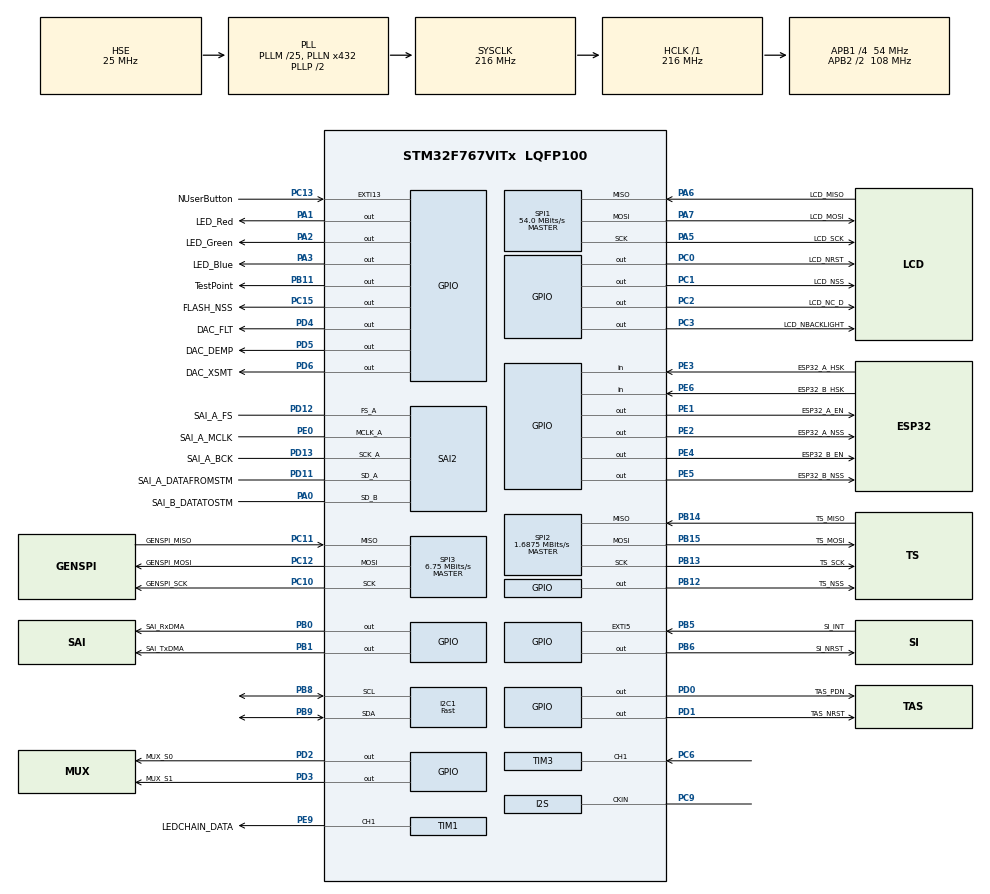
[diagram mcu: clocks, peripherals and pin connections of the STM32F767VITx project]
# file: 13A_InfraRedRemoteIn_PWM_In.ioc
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CORTEX_M7.CPU_DCache=Enabled
CORTEX_M7.CPU_ICache=Enabled
Dma.I2C1_RX.1.Direction=DMA_PERIPH_TO_MEMORY
Dma.I2C1_RX.1.FIFOMode=DMA_FIFOMODE_DISABLE
Dma.I2C1_RX.1.Instance=DMA1_Stream0
Dma.I2C1_RX.1.MemDataAlignment=DMA_MDATAALIGN_BYTE
Dma.I2C1_RX.1.MemInc=DMA_MINC_ENABLE
Dma.I2C1_RX.1.Mode=DMA_NORMAL
Dma.I2C1_RX.1.PeriphDataAlignment=DMA_PDATAALIGN_BYTE
Dma.I2C1_RX.1.PeriphInc=DMA_PINC_DISABLE
Dma.I2C1_RX.1.Priority=DMA_PRIORITY_HIGH
Dma.I2C1_TX.0.Direction=DMA_MEMORY_TO_PERIPH
Dma.I2C1_TX.0.FIFOMode=DMA_FIFOMODE_DISABLE
Dma.I2C1_TX.0.Instance=DMA1_Stream7
Dma.I2C1_TX.0.MemDataAlignment=DMA_MDATAALIGN_BYTE
Dma.I2C1_TX.0.MemInc=DMA_MINC_ENABLE
Dma.I2C1_TX.0.Mode=DMA_NORMAL
Dma.I2C1_TX.0.PeriphDataAlignment=DMA_PDATAALIGN_BYTE
Dma.I2C1_TX.0.PeriphInc=DMA_PINC_DISABLE
Dma.I2C1_TX.0.Priority=DMA_PRIORITY_HIGH
Dma.Request0=I2C1_TX
Dma.Request1=I2C1_RX
Dma.Request2=SPI1_TX
Dma.Request3=SAI2_A
Dma.Request4=SAI2_B
Dma.Request5=TIM1_CH1
Dma.Request6=SPI3_TX
Dma.SAI2_A.3.Direction=DMA_MEMORY_TO_PERIPH
Dma.SAI2_A.3.FIFOMode=DMA_FIFOMODE_DISABLE
Dma.SAI2_A.3.Instance=DMA2_Stream2
Dma.SAI2_A.3.MemDataAlignment=DMA_MDATAALIGN_WORD
Dma.SAI2_A.3.MemInc=DMA_MINC_ENABLE
Dma.SAI2_A.3.Mode=DMA_CIRCULAR
Dma.SAI2_A.3.PeriphDataAlignment=DMA_PDATAALIGN_WORD
Dma.SAI2_A.3.PeriphInc=DMA_PINC_DISABLE
Dma.SAI2_A.3.Priority=DMA_PRIORITY_HIGH
Dma.SAI2_B.4.Direction=DMA_PERIPH_TO_MEMORY
Dma.SAI2_B.4.FIFOMode=DMA_FIFOMODE_DISABLE
Dma.SAI2_B.4.Instance=DMA2_Stream6
Dma.SAI2_B.4.MemDataAlignment=DMA_MDATAALIGN_WORD
Dma.SAI2_B.4.MemInc=DMA_MINC_ENABLE
Dma.SAI2_B.4.Mode=DMA_CIRCULAR
Dma.SAI2_B.4.PeriphDataAlignment=DMA_PDATAALIGN_WORD
Dma.SAI2_B.4.PeriphInc=DMA_PINC_DISABLE
Dma.SAI2_B.4.Priority=DMA_PRIORITY_HIGH
Dma.SPI1_TX.2.Direction=DMA_MEMORY_TO_PERIPH
Dma.SPI1_TX.2.FIFOMode=DMA_FIFOMODE_ENABLE
Dma.SPI1_TX.2.FIFOThreshold=DMA_FIFO_THRESHOLD_FULL
Dma.SPI1_TX.2.Instance=DMA2_Stream3
Dma.SPI1_TX.2.MemBurst=DMA_MBURST_SINGLE
Dma.SPI1_TX.2.MemDataAlignment=DMA_MDATAALIGN_BYTE
Dma.SPI1_TX.2.MemInc=DMA_MINC_ENABLE
Dma.SPI1_TX.2.Mode=DMA_NORMAL
Dma.SPI1_TX.2.PeriphBurst=DMA_PBURST_SINGLE
Dma.SPI1_TX.2.PeriphDataAlignment=DMA_PDATAALIGN_BYTE
Dma.SPI1_TX.2.PeriphInc=DMA_PINC_DISABLE
Dma.SPI1_TX.2.Priority=DMA_PRIORITY_MEDIUM
Dma.SPI3_TX.6.Direction=DMA_MEMORY_TO_PERIPH
Dma.SPI3_TX.6.FIFOMode=DMA_FIFOMODE_ENABLE
Dma.SPI3_TX.6.FIFOThreshold=DMA_FIFO_THRESHOLD_FULL
Dma.SPI3_TX.6.Instance=DMA1_Stream5
Dma.SPI3_TX.6.MemBurst=DMA_MBURST_SINGLE
Dma.SPI3_TX.6.MemDataAlignment=DMA_MDATAALIGN_BYTE
Dma.SPI3_TX.6.MemInc=DMA_MINC_ENABLE
Dma.SPI3_TX.6.Mode=DMA_NORMAL
Dma.SPI3_TX.6.PeriphBurst=DMA_PBURST_SINGLE
Dma.SPI3_TX.6.PeriphDataAlignment=DMA_PDATAALIGN_BYTE
Dma.SPI3_TX.6.PeriphInc=DMA_PINC_DISABLE
Dma.SPI3_TX.6.Priority=DMA_PRIORITY_HIGH
Dma.TIM1_CH1.5.Direction=DMA_MEMORY_TO_PERIPH
Dma.TIM1_CH1.5.FIFOMode=DMA_FIFOMODE_ENABLE
Dma.TIM1_CH1.5.FIFOThreshold=DMA_FIFO_THRESHOLD_FULL
Dma.TIM1_CH1.5.Instance=DMA2_Stream1
Dma.TIM1_CH1.5.MemBurst=DMA_MBURST_SINGLE
Dma.TIM1_CH1.5.MemDataAlignment=DMA_MDATAALIGN_HALFWORD
Dma.TIM1_CH1.5.MemInc=DMA_MINC_ENABLE
Dma.TIM1_CH1.5.Mode=DMA_NORMAL
Dma.TIM1_CH1.5.PeriphBurst=DMA_PBURST_SINGLE
Dma.TIM1_CH1.5.PeriphDataAlignment=DMA_PDATAALIGN_HALFWORD
Dma.TIM1_CH1.5.PeriphInc=DMA_PINC_DISABLE
Dma.TIM1_CH1.5.Priority=DMA_PRIORITY_MEDIUM
I2C1.I2C_Speed_Mode=I2C_Fast
I2C1.Timing=0x6000030D
Mcu.Family=STM32F7
Mcu.Name=STM32F767VITx
Mcu.Package=LQFP100
NVIC.DMA1_Stream0_IRQn=true\:0\:0\:false\:false\:true\:false\:true
NVIC.DMA1_Stream5_IRQn=true\:0\:0\:false\:false\:true\:false\:true
NVIC.DMA1_Stream7_IRQn=true\:0\:0\:false\:false\:true\:false\:true
NVIC.DMA2_Stream1_IRQn=true\:0\:0\:false\:false\:true\:false\:true
NVIC.DMA2_Stream2_IRQn=true\:0\:0\:false\:false\:true\:false\:true
NVIC.DMA2_Stream3_IRQn=true\:0\:0\:false\:false\:true\:false\:true
NVIC.DMA2_Stream6_IRQn=true\:0\:0\:false\:false\:true\:false\:true
NVIC.EXTI15_10_IRQn=true\:0\:0\:false\:false\:true\:true\:true
NVIC.EXTI9_5_IRQn=true\:0\:0\:false\:false\:true\:true\:true
NVIC.I2C1_ER_IRQn=true\:0\:0\:false\:false\:true\:true\:true
NVIC.I2C1_EV_IRQn=true\:0\:0\:false\:false\:true\:true\:true
NVIC.PriorityGroup=NVIC_PRIORITYGROUP_4
NVIC.TIM1_TRG_COM_TIM11_IRQn=true\:0\:0\:false\:false\:true\:true\:true
NVIC.TIM3_IRQn=true\:0\:0\:false\:false\:true\:true\:true
PA0/WKUP.GPIO_Label=SAI_B_DATATOSTM
PA0/WKUP.Mode=SAI_B_SyncSlave
PA0/WKUP.Signal=SAI2_SD_B
PA1.GPIO_Label=LED_Red
PA1.Signal=GPIO_Output
PA13.GPIO_Label=SWDIO
PA13.Mode=Serial_Wire
PA13.Signal=SYS_JTMS-SWDIO
PA14.GPIO_Label=SWCLK
PA14.Mode=Serial_Wire
PA14.Signal=SYS_JTCK-SWCLK
PA2.GPIO_Label=LED_Green
PA2.Signal=GPIO_Output
PA3.GPIO_Label=LED_Blue
PA3.Signal=GPIO_Output
PA5.GPIO_Label=LCD_SCK
PA5.Mode=Full_Duplex_Master
PA5.Signal=SPI1_SCK
PA6.GPIO_Label=LCD_MISO
PA6.Mode=Full_Duplex_Master
PA6.Signal=SPI1_MISO
PA7.GPIO_Label=LCD_MOSI
PA7.Mode=Full_Duplex_Master
PA7.Signal=SPI1_MOSI
PB0.GPIO_Label=SAI_RxDMA
PB0.GPIO_Speed=GPIO_SPEED_FREQ_HIGH
PB0.Signal=GPIO_Output
PB1.GPIO_Label=SAI_TxDMA
PB1.GPIO_Speed=GPIO_SPEED_FREQ_HIGH
PB1.Signal=GPIO_Output
PB11.GPIO_Label=TestPoint
PB11.GPIO_Speed=GPIO_SPEED_FREQ_HIGH
PB11.PinState=GPIO_PIN_RESET
PB11.Signal=GPIO_Output
PB12.GPIO_Label=TS_NSS
PB12.Signal=GPIO_Output
PB13.GPIO_Label=TS_SCK
PB13.Mode=Full_Duplex_Master
PB13.Signal=SPI2_SCK
PB14.GPIO_Label=TS_MISO
PB14.Mode=Full_Duplex_Master
PB14.Signal=SPI2_MISO
PB15.GPIO_Label=TS_MOSI
PB15.Mode=Full_Duplex_Master
PB15.Signal=SPI2_MOSI
PB5.GPIO_Label=SI_INT
PB5.GPIO_ModeDefaultEXTI=GPIO_MODE_IT_FALLING
PB5.Signal=GPXTI5
PB6.GPIO_Label=SI_NRST
PB6.Signal=GPIO_Output
PB8.Mode=I2C
PB8.Signal=I2C1_SCL
PB9.Mode=I2C
PB9.Signal=I2C1_SDA
PC0.GPIO_Label=LCD_NRST
PC0.Signal=GPIO_Output
PC1.GPIO_Label=LCD_NSS
PC1.Signal=GPIO_Output
PC10.GPIO_Label=GENSPI_SCK
PC10.Mode=Full_Duplex_Master
PC10.Signal=SPI3_SCK
PC11.GPIO_Label=GENSPI_MISO
PC11.Mode=Full_Duplex_Master
PC11.Signal=SPI3_MISO
PC12.GPIO_Label=GENSPI_MOSI
PC12.Mode=Full_Duplex_Master
PC12.Signal=SPI3_MOSI
PC13.GPIO_Label=NUserButton
PC13.GPIO_ModeDefaultEXTI=GPIO_MODE_IT_FALLING
PC13.GPIO_PuPd=GPIO_PULLUP
PC13.Signal=GPXTI13
PC15/OSC32_OUT.GPIO_Label=FLASH_NSS
PC15/OSC32_OUT.PinState=GPIO_PIN_SET
PC15/OSC32_OUT.Signal=GPIO_Output
PC2.GPIO_Label=LCD_NC_D
PC2.Signal=GPIO_Output
PC3.GPIO_Label=LCD_NBACKLIGHT
PC3.Signal=GPIO_Output
PC6.Signal=S_TIM3_CH1
PC9.Mode=Audio_ClockIn
PC9.Signal=I2S_CKIN
PD0.GPIO_Label=TAS_PDN
PD0.Signal=GPIO_Output
PD1.GPIO_Label=TAS_NRST
PD1.Signal=GPIO_Output
PD11.GPIO_Label=SAI_A_DATAFROMSTM
PD11.Mode=SAI_A_MasterWithClock
PD11.Signal=SAI2_SD_A
PD12.GPIO_Label=SAI_A_FS
PD12.Mode=SAI_A_MasterWithClock
PD12.Signal=SAI2_FS_A
PD13.GPIO_Label=SAI_A_BCK
PD13.Mode=SAI_A_MasterWithClock
PD13.Signal=SAI2_SCK_A
PD2.GPIO_Label=MUX_S0
PD2.Signal=GPIO_Output
PD3.GPIO_Label=MUX_S1
PD3.Signal=GPIO_Output
PD4.GPIO_Label=DAC_FLT
PD4.Signal=GPIO_Output
PD5.GPIO_Label=DAC_DEMP
PD5.Signal=GPIO_Output
PD6.GPIO_Label=DAC_XSMT
PD6.Signal=GPIO_Output
PE0.GPIO_Label=SAI_A_MCLK
PE0.Mode=SAI_A_MasterWithClock
PE0.Signal=SAI2_MCLK_A
PE1.GPIO_Label=ESP32_A_EN
PE1.GPIO_Speed=GPIO_SPEED_FREQ_LOW
PE1.PinState=GPIO_PIN_RESET
PE1.Signal=GPIO_Output
PE2.GPIO_Label=ESP32_A_NSS
PE2.GPIO_Speed=GPIO_SPEED_FREQ_HIGH
PE2.PinState=GPIO_PIN_SET
PE2.Signal=GPIO_Output
PE3.GPIO_Label=ESP32_A_HSK
PE3.Signal=GPIO_Input
PE4.GPIO_Label=ESP32_B_EN
PE4.GPIO_Speed=GPIO_SPEED_FREQ_LOW
PE4.PinState=GPIO_PIN_RESET
PE4.Signal=GPIO_Output
PE5.GPIO_Label=ESP32_B_NSS
PE5.GPIO_Speed=GPIO_SPEED_FREQ_HIGH
PE5.PinState=GPIO_PIN_SET
PE5.Signal=GPIO_Output
PE6.GPIO_Label=ESP32_B_HSK
PE6.Signal=GPIO_Input
PE9.GPIO_Label=LEDCHAIN_DATA
PE9.GPIO_Speed=GPIO_SPEED_FREQ_HIGH
PE9.Signal=S_TIM1_CH1
PH0/OSC_IN.GPIO_Label=MCU_CLK_IN
PH0/OSC_IN.Mode=HSE-External-Clock-Source
PH0/OSC_IN.Signal=RCC_OSC_IN
PH1/OSC_OUT.Mode=HSE-External-Clock-Source
PH1/OSC_OUT.Signal=RCC_OSC_OUT
ProjectManager.HeapSize=0x2000
ProjectManager.StackSize=0x4000
ProjectManager.TargetToolchain=TrueSTUDIO
RCC.AHBFreq_Value=216000000
RCC.APB1CLKDivider=RCC_HCLK_DIV4
RCC.APB1Freq_Value=54000000
RCC.APB1TimFreq_Value=108000000
RCC.APB2CLKDivider=RCC_HCLK_DIV2
RCC.APB2Freq_Value=108000000
RCC.APB2TimFreq_Value=216000000
RCC.CortexFreq_Value=216000000
RCC.EXTERNAL_CLOCK_VALUE=11289600
RCC.HCLKFreq_Value=216000000
RCC.HSE_VALUE=25000000
RCC.HSI_VALUE=16000000
RCC.LSE_VALUE=32768
RCC.PLLI2SN=344
RCC.PLLI2SQ=14
RCC.PLLM=25
RCC.PLLN=432
RCC.PLLSAIN=429
RCC.PLLSAIQDiv=19
RCC.PLLSourceVirtual=RCC_PLLSOURCE_HSE
RCC.SAI2CLockSelection=RCC_SAI2CLKSOURCE_PLLI2S
RCC.SYSCLKFreq_VALUE=216000000
RCC.SYSCLKSource=RCC_SYSCLKSOURCE_PLLCLK
RCC.USBFreq_Value=216000000
RCC.VCOOutputFreq_Value=432000000
SAI2.AudioFrequency-SAI_A_MasterWithClock=SAI_AUDIO_FREQUENCY_48K
SAI2.BasicDataSize-SAI_A_MasterWithClock=SAI_PROTOCOL_DATASIZE_24BIT
SAI2.BasicDataSize-SAI_B_SyncSlave=SAI_PROTOCOL_DATASIZE_24BIT
SAI2.ErrorAudioFreq-SAI_A_MasterWithClock=-0.01 %
SAI2.InitProtocol-SAI_A_MasterWithClock=Enable
SAI2.InitProtocol-SAI_B_SyncSlave=Enable
SAI2.Instance-SAI_A_MasterWithClock=SAI$Index_Block_A
SAI2.Instance-SAI_B_SyncSlave=SAI$Index_Block_B
SAI2.MClockEnable-SAI_A_MasterWithClock=SAI_MASTERCLOCK_ENABLE
SAI2.NoDivider-SAI_A_MasterWithClock=SAI_MASTERDIVIDER_ENABLE
SAI2.RealAudioFreq-SAI_A_MasterWithClock=47.991 KHz
SAI2.Synchro-SAI_A_MasterWithClock=SAI_ASYNCHRONOUS
SAI2.Synchro-SAI_B_SyncSlave=SAI_SYNCHRONOUS
SAI2.VirtualMode-SAI_A_MasterWithClock=VM_MASTER
SAI2.VirtualMode-SAI_B_SyncSlave=VM_SLAVE
SAI2.VirtualProtocol-SAI_A_BASIC=VM_BASIC_PROTOCOL
SAI2.VirtualProtocol-SAI_B_BASIC=VM_BASIC_PROTOCOL
SH.S_TIM1_CH1.0=TIM1_CH1,PWM Generation1 CH1
SH.S_TIM3_CH1.0=TIM3_CH1,Input_Capture1_from_TI1
SH.S_TIM3_CH1.1=TIM3_CH1,Input_Capture2_from_TI1
SH.S_TIM3_CH1.2=TIM3_CH1,TriggerSource_TI1FP1
SPI1.BaudRatePrescaler=SPI_BAUDRATEPRESCALER_2
SPI1.CalculateBaudRate=54.0 MBits/s
SPI1.DataSize=SPI_DATASIZE_8BIT
SPI1.Direction=SPI_DIRECTION_2LINES
SPI1.Mode=SPI_MODE_MASTER
SPI1.VirtualType=VM_MASTER
SPI2.BaudRatePrescaler=SPI_BAUDRATEPRESCALER_32
SPI2.CalculateBaudRate=1.6875 MBits/s
SPI2.DataSize=SPI_DATASIZE_8BIT
SPI2.Direction=SPI_DIRECTION_2LINES
SPI2.Mode=SPI_MODE_MASTER
SPI2.VirtualType=VM_MASTER
SPI3.BaudRatePrescaler=SPI_BAUDRATEPRESCALER_8
SPI3.CalculateBaudRate=6.75 MBits/s
SPI3.DataSize=SPI_DATASIZE_8BIT
SPI3.Direction=SPI_DIRECTION_2LINES
SPI3.Mode=SPI_MODE_MASTER
SPI3.VirtualType=VM_MASTER
TIM1.AutoReloadPreload=TIM_AUTORELOAD_PRELOAD_ENABLE
TIM1.Channel-PWM\ Generation1\ CH1=TIM_CHANNEL_1
TIM1.OCIdleState_1=TIM_OCIDLESTATE_RESET
TIM1.OCPolarity_1=TIM_OCPOLARITY_HIGH
TIM1.Period=269
TIM1.Pulse-PWM\ Generation1\ CH1=0
TIM3.Channel-Input_Capture1_from_TI1=TIM_CHANNEL_1
TIM3.Channel-Input_Capture2_from_TI1=TIM_CHANNEL_2
TIM3.ICPolarity_CH1=TIM_INPUTCHANNELPOLARITY_RISING
TIM3.ICPolarity_CH2=TIM_INPUTCHANNELPOLARITY_FALLING
TIM3.Period=3599
TIM3.Prescaler=107
TIM3.TIM_MasterSlaveMode=TIM_MASTERSLAVEMODE_DISABLE
VP_SAI2_VP_$IpInstance_SAIA_SAI_BASIC.Mode=SAI_A_BASIC
VP_SAI2_VP_$IpInstance_SAIB_SAI_BASIC.Mode=SAI_B_BASIC
VP_TIM3_VS_ClockSourceINT.Mode=Internal
VP_TIM3_VS_ControllerModeReset.Mode=Reset Mode
board=07_SPDIF_to_DAC+PA

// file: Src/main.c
/* USER CODE BEGIN Header */
/**
  ******************************************************************************
  * @file           : main.c
  * @brief          : Main program body
  ******************************************************************************
  ** This notice applies to any and all portions of this file
  * that are not between comment pairs USER CODE BEGIN and
  * USER CODE END. Other portions of this file, whether
  * inserted by the user or by software development tools
  * are owned by their respective copyright owners.
  *
  * COPYRIGHT(c) 2018 STMicroelectronics
  *
  * Redistribution and use in source and binary forms, with or without modification,
  * are permitted provided that the following conditions are met:
  *   1. Redistributions of source code must retain the above copyright notice,
  *      this list of conditions and the following disclaimer.
  *   2. Redistributions in binary form must reproduce the above copyright notice,
  *      this list of conditions and the following disclaimer in the documentation
  *      and/or other materials provided with the distribution.
  *   3. Neither the name of STMicroelectronics nor the names of its contributors
  *      may be used to endorse or promote products derived from this software
  *      without specific prior written permission.
  *
  * THIS SOFTWARE IS PROVIDED BY THE COPYRIGHT HOLDERS AND CONTRIBUTORS "AS IS"
  * AND ANY EXPRESS OR IMPLIED WARRANTIES, INCLUDING, BUT NOT LIMITED TO, THE
  * IMPLIED WARRANTIES OF MERCHANTABILITY AND FITNESS FOR A PARTICULAR PURPOSE ARE
  * DISCLAIMED. IN NO EVENT SHALL THE COPYRIGHT HOLDER OR CONTRIBUTORS BE LIABLE
  * FOR ANY DIRECT, INDIRECT, INCIDENTAL, SPECIAL, EXEMPLARY, OR CONSEQUENTIAL
  * DAMAGES (INCLUDING, BUT NOT LIMITED TO, PROCUREMENT OF SUBSTITUTE GOODS OR
  * SERVICES; LOSS OF USE, DATA, OR PROFITS; OR BUSINESS INTERRUPTION) HOWEVER
  * CAUSED AND ON ANY THEORY OF LIABILITY, WHETHER IN CONTRACT, STRICT LIABILITY,
  * OR TORT (INCLUDING NEGLIGENCE OR OTHERWISE) ARISING IN ANY WAY OUT OF THE USE
  * OF THIS SOFTWARE, EVEN IF ADVISED OF THE POSSIBILITY OF SUCH DAMAGE.
  *
  ******************************************************************************
  */
/* USER CODE END Header */

#include "main.h"
#include "dma.h"
#include "i2c.h"
#include "sai.h"
#include "spi.h"
#include "tim.h"
#include "gpio.h"

/* USER CODE BEGIN Includes */

#include "PJB_STM32_ESP32_FM_DAB_ADC_DAC_PA.h"
#include "go.h"

/* USER CODE END Includes */

/* USER CODE BEGIN PV */
/* Private variables ---------------------------------------------------------*/

/* USER CODE END PV */

void SystemClock_Config(void);
/* USER CODE BEGIN PFP */
/* Private function prototypes -----------------------------------------------*/

/* USER CODE END PFP */

int main(void)
{

  /* Enable I-Cache---------------------------------------------------------*/
  SCB_EnableICache();

  /* Enable D-Cache---------------------------------------------------------*/
  SCB_EnableDCache();

  /* MCU Configuration--------------------------------------------------------*/

  /* Reset of all peripherals, Initializes the Flash interface and the Systick. */
  HAL_Init();

  /* Configure the system clock */
  SystemClock_Config();

  /* Initialize all configured peripherals */
  MX_GPIO_Init();
  MX_DMA_Init();
  MX_I2C1_Init();
  MX_SPI1_Init();
  MX_SPI2_Init();
  MX_SPI3_Init();
  MX_TIM1_Init();
  MX_SAI2_Init();
  MX_TIM3_Init();
  /* USER CODE BEGIN 2 */

  Go();

  /* USER CODE END 2 */

  /* Infinite loop */
  while (1)
  {

  }
}

void SystemClock_Config(void)
{
  RCC_OscInitTypeDef RCC_OscInitStruct = {0};
  RCC_ClkInitTypeDef RCC_ClkInitStruct = {0};
  RCC_PeriphCLKInitTypeDef PeriphClkInitStruct = {0};

  /** Configure the main internal regulator output voltage
  */
  __HAL_RCC_PWR_CLK_ENABLE();
  __HAL_PWR_VOLTAGESCALING_CONFIG(PWR_REGULATOR_VOLTAGE_SCALE1);
  /** Initializes the CPU, AHB and APB busses clocks
  */
  RCC_OscInitStruct.OscillatorType = RCC_OSCILLATORTYPE_HSE;
  RCC_OscInitStruct.HSEState = RCC_HSE_BYPASS;
  RCC_OscInitStruct.PLL.PLLState = RCC_PLL_ON;
  RCC_OscInitStruct.PLL.PLLSource = RCC_PLLSOURCE_HSE;
  RCC_OscInitStruct.PLL.PLLM = 25;
  RCC_OscInitStruct.PLL.PLLN = 432;
  RCC_OscInitStruct.PLL.PLLP = RCC_PLLP_DIV2;
  RCC_OscInitStruct.PLL.PLLQ = 2;
  if (HAL_RCC_OscConfig(&RCC_OscInitStruct) != HAL_OK)
  {
    Error_Handler();
  }
  /** Activate the Over-Drive mode
  */
  if (HAL_PWREx_EnableOverDrive() != HAL_OK)
  {
    Error_Handler();
  }
  /** Initializes the CPU, AHB and APB busses clocks
  */
  RCC_ClkInitStruct.ClockType = RCC_CLOCKTYPE_HCLK|RCC_CLOCKTYPE_SYSCLK
                              |RCC_CLOCKTYPE_PCLK1|RCC_CLOCKTYPE_PCLK2;
  RCC_ClkInitStruct.SYSCLKSource = RCC_SYSCLKSOURCE_PLLCLK;
  RCC_ClkInitStruct.AHBCLKDivider = RCC_SYSCLK_DIV1;
  RCC_ClkInitStruct.APB1CLKDivider = RCC_HCLK_DIV4;
  RCC_ClkInitStruct.APB2CLKDivider = RCC_HCLK_DIV2;

  if (HAL_RCC_ClockConfig(&RCC_ClkInitStruct, FLASH_LATENCY_7) != HAL_OK)
  {
    Error_Handler();
  }
  PeriphClkInitStruct.PeriphClockSelection = RCC_PERIPHCLK_SAI2|RCC_PERIPHCLK_I2C1;
  PeriphClkInitStruct.PLLI2S.PLLI2SN = 344;
  PeriphClkInitStruct.PLLI2S.PLLI2SP = RCC_PLLP_DIV2;
  PeriphClkInitStruct.PLLI2S.PLLI2SR = 2;
  PeriphClkInitStruct.PLLI2S.PLLI2SQ = 14;
  PeriphClkInitStruct.PLLI2SDivQ = 1;
  PeriphClkInitStruct.Sai2ClockSelection = RCC_SAI2CLKSOURCE_PLLI2S;
  PeriphClkInitStruct.I2c1ClockSelection = RCC_I2C1CLKSOURCE_PCLK1;
  if (HAL_RCCEx_PeriphCLKConfig(&PeriphClkInitStruct) != HAL_OK)
  {
    Error_Handler();
  }
}

void Error_Handler(void)
{
  /* USER CODE BEGIN Error_Handler_Debug */
  /* User can add his own implementation to report the HAL error return state */
  while(1)
  {
    ToggleLED(LED_Red);
    HAL_Delay(50);
    ToggleLED(LED_Red);
    HAL_Delay(50);
  }
  /* USER CODE END Error_Handler_Debug */
}

/************************ (C) COPYRIGHT STMicroelectronics *****END OF FILE****/
